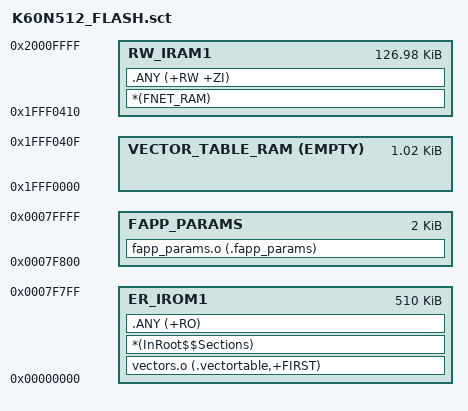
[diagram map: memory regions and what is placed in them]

; *************************************************************
; *** Scatter-Loading Description File generated by uVision ***
; *************************************************************

LR_IROM1 0x00000000 0x0007F800  
{   
    ER_IROM1 0x00000000 0x00080000-0x800  
    {
        vectors.o (.vectortable,+FIRST)                  ; ROM Vector Table
        *(InRoot$$Sections)
        .ANY (+RO)
    }

 
    VECTOR_TABLE_RAM 0x1FFF0000 EMPTY 0x410  ; RAM Vector Table
    {
    }
  
    RW_IRAM1 0x1FFF0410 0x00020000-0x410  
    { 
        *(FNET_RAM) 			                            ; FNET Flash driver inram function
        .ANY (+RW +ZI)
    }
}

LR_IROM2 0x0007F800 0x00000800
{
    FAPP_PARAMS 0x0007F800 0x00000800 		; 2KBytes = Last logical-block resevrd for params.
	{
        fapp_params.o (.fapp_params)
    }
}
